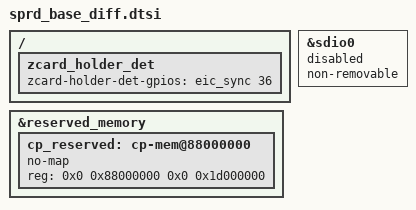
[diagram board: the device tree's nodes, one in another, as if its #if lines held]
/*
 * this file is ued to change sprd dtsi which can't be changed by overlay
 * such as /delete-node/ /delete-property/ and alises
 */
#include <generated/autoconf.h>
#include "zte_touchscreen.dtsi"
#include "zte_audio.dtsi"
#include "zte_nfc_pn557.dtsi"
#include "zte_camera.dtsi"
#ifdef CONFIG_CHARGER_2CP_USE_1CP
#include "zte_charger_use_1cp.dtsi"
#else
#include "zte_charger.dtsi"
#endif
#include "zte_fingerprint.dtsi"
#include "zte_breath_led.dtsi"
#include "zte_sar.dtsi"
#include "zte_skey.dtsi"
#include "zte_haptic_hv.dtsi"
#include "../../thermal/ntc-nr.dtsi"
#include "../../thermal/ntc-flash.dtsi"

/{
        zcard_holder_det {
                zcard-holder-det-gpios= <&eic_sync 36 GPIO_ACTIVE_HIGH>;
        };
};

&sdio0 {
	status = "disabled";
	non-removable;
};

/*sprd patch for T ota to U, config modem 23A only */
&reserved_memory {
	/delete-node/ nrphy-iqmem@0xa2400000;

	cp_reserved: cp-mem@88000000 {
	no-map;
	reg = <0x0 0x88000000 0x0 0x1d000000>;
	};
};
